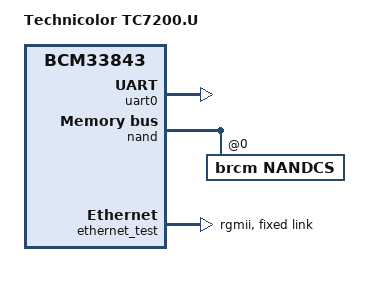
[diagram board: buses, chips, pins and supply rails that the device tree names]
// SPDX-License-Identifier: GPL-2.0
/dts-v1/;

#include "bcm3384_viper.dtsi"

/ {
	compatible = "technicolor,tc7200u", "brcm,bcm3384-viper", "brcm,bcm33843-viper";
	model = "Technicolor TC7200.U";

	chosen {
		bootargs = "console=ttyS0,115200 earlycon";
		stdout-path = &uart0;
	};
};

&uart0 {
	reg = <0x14e00500 0x18>;
	interrupt-parent = <&periph_intc>;
	interrupts = <2>;
	clocks = <&periph_clk>;
	status = "okay";
};
/* TC7200.U SPI NOR probe. Disabled after invalid boot/panic. RAM-boot only. */
&{/ubus} {
        spi: spi@14e01000 {
                compatible = "brcm,bcm6328-hsspi";
                reg = <0x14e01000 0x600>;

                #address-cells = <1>;
                #size-cells = <0>;

                interrupt-parent = <&periph_intc>;
                interrupts = <7>;

                clocks = <&periph_clk>;
                clock-names = "hsspi";

                status = "disabled";

                flash@0 {
                        compatible = "jedec,spi-nor";
                        reg = <0>;
                        spi-max-frequency = <10000000>;
                };
        };
};

/* Temporary TC7200.U NAND probe node. RAM-boot test only. Do not flash. */
&{/ubus} {
	iop_intc: iop_intc@14e00050 {
		compatible = "brcm,bcm3380-l2-intc";
		reg = <0x14e00050 0x4 0x14e00054 0x4>;

		interrupt-controller;
		#interrupt-cells = <1>;

		interrupt-parent = <&cpu_intc>;
		interrupts = <5>;
	};

	nand: nand@14e02200 {
		compatible = "brcm,nand-bcm6368", "brcm,brcmnand-v4.0", "brcm,brcmnand";
		reg-names = "nand", "nand-int-base", "nand-cache";
		reg = <0x14e02200 0x180>, <0x14e000f0 0x10>, <0x14e02600 0x200>;

		#address-cells = <1>;
		#size-cells = <0>;

		interrupt-parent = <&periph_intc>;
		interrupts = <3>;

		status = "okay";

		nandcs@0 {
			compatible = "brcm,nandcs";
			reg = <0>;
			nand-ecc-strength = <1>;
			nand-ecc-step-size = <512>;

			#address-cells = <1>;
			#size-cells = <1>;
		};
	};

};
/* Temporary TC7200.U GENET fixed-link diagnostic. RAM-boot only. */
&{/ubus} {
	ethernet_test: ethernet@12c00000 {
		compatible = "brcm,genet-v1";
		reg = <0x12c00000 0x4000>;

		interrupt-parent = <&periph_intc>;
		interrupts = <16>;

		phy-mode = "rgmii";
		status = "okay";

		fixed-link {
			speed = <1000>;
			full-duplex;
		};
	};
};
